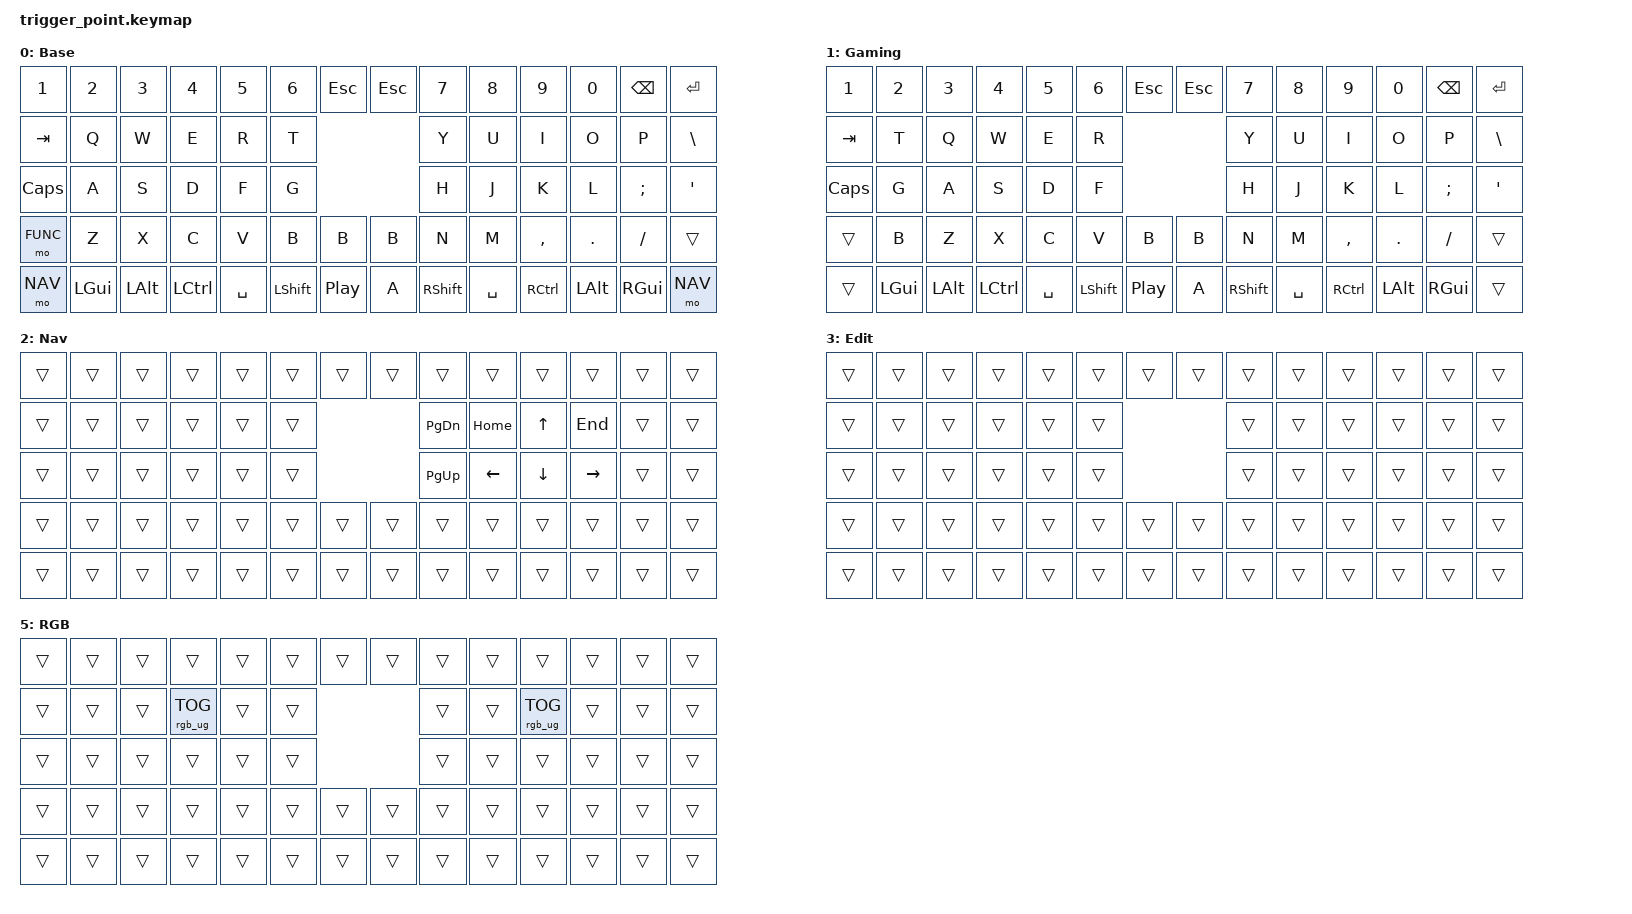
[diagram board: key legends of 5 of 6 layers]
#include <behaviors.dtsi>
#include <dt-bindings/zmk/keys.h>
#include <dt-bindings/zmk/bt.h>
#include <dt-bindings/zmk/outputs.h>
#include <dt-bindings/zmk/rgb.h>

#define BASE    0
#define GAM     1
#define NAV     2
#define EDIT    3
#define FUNC    4
#define RGB     5


#include "combos.dtsi"


/ {
    behaviors {
        rot_kp: sensor_rotate_kp {
            compatible = "zmk,behavior-sensor-rotate-var";
            #sensor-binding-cells = <2>;
            bindings = <&kp>, <&kp>;
        };
    };

    keymap {
        compatible = "zmk,keymap";

        default_layer {
          display-name = "Base";
            sensor-bindings = <&rot_kp C_PREV C_NEXT>, <&rot_kp LEFT RIGHT>;
            // For sensors first is left pot then right pot. CCW then CW
            bindings = <
            // ╭─────────────┬─────────────┬─────────────┬─────────────┬─────────────┬─────────────┬─────────────╮  ╭─────────────┬─────────────┬─────────────┬─────────────┬─────────────┬─────────────┬─────────────╮
            // |   Number 1  |   Number 2  |   Number 3  |   Number 4  |   Number 5  |   Number 6  |    Escape   |  |    Escape   |   Number 7  |   Number 8  |   Number 9  |   Number 0  |  Backspace  |    Enter    |
                    &kp N1        &kp N2        &kp N3        &kp N4        &kp N5        &kp N6       &kp ESC          &kp ESC        &kp N7        &kp N8        &kp N9        &kp N0      &kp BSPC       &kp RET  
            // ├─────────────┼─────────────┼─────────────┼─────────────┼─────────────┼─────────────┼─────────────┤  ├─────────────┼─────────────┼─────────────┼─────────────┼─────────────┼─────────────┼─────────────┤
            // |     Tab     |      Q      |      W      |      E      |      R      |      T      |             |  |             |      Y      |      U      |      I      |       O     |       P     |     Pipe    |
                   &kp TAB        &kp Q         &kp W         &kp E         &kp R         &kp T                                        &kp Y         &kp U         &kp I          &kp O         &kp P      &kp BSLH
            // ├─────────────┼─────────────┼─────────────┼─────────────┼─────────────┼─────────────┼─────────────┤  ├─────────────┼─────────────┼─────────────┼─────────────┼─────────────┼─────────────┼─────────────┤
            // |      ^      |      A      |      S      |      D      |      F      |      G      |             |  |             |      H      |      J      |      K      |      L      |      ;      |  Apostrophe |
                  &kp CAPS        &kp A         &kp S         &kp D         &kp F         &kp G                                        &kp H         &kp J         &kp K          &kp L       &kp SEMI     &kp APOS
            // ├─────────────┼─────────────┼─────────────┼─────────────┼─────────────┼─────────────┼─────────────┤  ├─────────────┼─────────────┼─────────────┼─────────────┼─────────────┼─────────────┼─────────────┤
            // |      ^      |      Z      |      X      |      C      |      V      |      B      |      ^      |  |      ^      |      N      |      M      |      ,      |      .      |      /      |      ^      |
                   &mo FUNC       &kp Z         &kp X         &kp C         &kp V         &kp B         &kp B           &kp B          &kp N         &kp M       &kp COMMA      &kp DOT      &kp SLASH      &trans
            // ├─────────────┼─────────────┼─────────────┼─────────────┼─────────────┼─────────────┼─────────────┤  ├─────────────┼─────────────┼─────────────┼─────────────┼─────────────┼─────────────┼─────────────┤
            // |      ^      |     GUI     |     ALT     |     CTRL    |   space     |    SHIFT    | Play/Pause  |  |      ^      |    SHIFT    |   space     |     CTRL    |     ALT     |     GUI     |      ^      |
                   &mo NAV       &kp LGUI     &kp LALT      &kp LCTRL     &kp SPACE    &kp LSHIFT     &kp C_PP           &kp A       &kp RSHIFT    &kp SPACE     &kp RCTRL     &kp LALT       &kp RGUI     &mo NAV   
            // ╰─────────────┴─────────────┴─────────────┴─────────────┴─────────────┴─────────────┴─────────────╯  ╰─────────────┴─────────────┴─────────────┴─────────────┴─────────────┴─────────────┴─────────────╯
            >;
        };

        gaming_layer {
            display-name = "Gaming";
            sensor-bindings = <&rot_kp C_PREV C_NEXT>, <&rot_kp LEFT RIGHT>;
            bindings = <
            // ╭─────────────┬─────────────┬─────────────┬─────────────┬─────────────┬─────────────┬─────────────╮  ╭─────────────┬─────────────┬─────────────┬─────────────┬─────────────┬─────────────┬─────────────╮
            // |   Number 1  |   Number 2  |   Number 3  |   Number 4  |   Number 5  |   Number 6  |    Escape   |  |    Escape   |   Number 7  |   Number 8  |   Number 9  |   Number 0  |  Backspace  |    Enter    |
                    &kp N1        &kp N2        &kp N3        &kp N4        &kp N5        &kp N6       &kp ESC          &kp ESC        &kp N7        &kp N8        &kp N9        &kp N0      &kp BSPC       &kp RET  
            // ├─────────────┼─────────────┼─────────────┼─────────────┼─────────────┼─────────────┼─────────────┤  ├─────────────┼─────────────┼─────────────┼─────────────┼─────────────┼─────────────┼─────────────┤
            // |     Tab     |      T      |      Q      |      W      |      E      |      R      |             |  |             |      Y      |      U      |      I      |       O     |       P     |     Pipe    |
                   &kp TAB        &kp T         &kp Q         &kp W         &kp E         &kp R                                        &kp Y         &kp U         &kp I          &kp O         &kp P      &kp BSLH
            // ├─────────────┼─────────────┼─────────────┼─────────────┼─────────────┼─────────────┼─────────────┤  ├─────────────┼─────────────┼─────────────┼─────────────┼─────────────┼─────────────┼─────────────┤
            // |      ^      |      G      |      A      |      S      |      D      |      F      |             |  |             |      H      |      J      |      K      |      L      |      ;      |  Apostrophe |
                  &kp CAPS        &kp G         &kp A         &kp S         &kp D         &kp F                                        &kp H         &kp J         &kp K          &kp L       &kp SEMI     &kp APOS
            // ├─────────────┼─────────────┼─────────────┼─────────────┼─────────────┼─────────────┼─────────────┤  ├─────────────┼─────────────┼─────────────┼─────────────┼─────────────┼─────────────┼─────────────┤
            // |      ^      |      B      |      Z      |      X      |      C      |      V      |      ^      |  |      ^      |      N      |      M      |      ,      |      .      |      /      |      ^      |
                   &trans         &kp B         &kp Z         &kp X         &kp C         &kp V         &kp B           &kp B          &kp N         &kp M       &kp COMMA      &kp DOT      &kp SLASH      &trans
            // ├─────────────┼─────────────┼─────────────┼─────────────┼─────────────┼─────────────┼─────────────┤  ├─────────────┼─────────────┼─────────────┼─────────────┼─────────────┼─────────────┼─────────────┤
            // |      ^      |     GUI     |     ALT     |     CTRL    |   space     |    SHIFT    | Play/Pause  |  |      ^      |    SHIFT    |   space     |     CTRL    |     ALT     |     GUI     |      ^      |
                   &trans        &kp LGUI     &kp LALT      &kp LCTRL     &kp SPACE    &kp LSHIFT     &kp C_PP           &kp A       &kp RSHIFT    &kp SPACE     &kp RCTRL     &kp LALT       &kp RGUI      &trans
            // ╰─────────────┴─────────────┴─────────────┴─────────────┴─────────────┴─────────────┴─────────────╯  ╰─────────────┴─────────────┴─────────────┴─────────────┴─────────────┴─────────────┴─────────────╯
            >;
        };

        nav_layer {
            sensor-bindings = <&rot_kp C_PREV C_NEXT>, <&rot_kp LEFT RIGHT>;
            display-name = "Nav";
            bindings = <
            // ╭─────────────┬─────────────┬─────────────┬─────────────┬─────────────┬─────────────┬─────────────╮  ╭─────────────┬─────────────┬─────────────┬─────────────┬─────────────┬─────────────┬─────────────╮
            // |      ^      |      ^      |      ^      |      ^      |      ^      |      ^      |      ^      |  |      ^      |      ^      |      ^      |      ^      |      ^      |      ^      |      ^      |
                   &trans        &trans        &trans        &trans        &trans        &trans        &trans           &trans        &trans        &trans        &trans        &trans        &trans        &trans   
            // ├─────────────┼─────────────┼─────────────┼─────────────┼─────────────┼─────────────┼─────────────┤  ├─────────────┼─────────────┼─────────────┼─────────────┼─────────────┼─────────────┼─────────────┤
            // |      ^      |      ^      |      ^      |      ^      |      ^      |      ^      |             |  |             |   Page Up   |    HOME     |      UP     |     END     |      ^      |      ^      |
                   &trans        &trans        &trans        &trans        &trans        &trans                                      &kp PG_DN      &kp HOME      &kp UP        &kp END       &trans        &trans   
            // ├─────────────┼─────────────┼─────────────┼─────────────┼─────────────┼─────────────┼─────────────┤  ├─────────────┼─────────────┼─────────────┼─────────────┼─────────────┼─────────────┼─────────────┤
            // |      ^      |      ^      |      ^      |      ^      |      ^      |      ^      |             |  |             |  Page Down  |    LEFT     |    DOWN     |   RIGHT     |      ^      |      ^      |
                   &trans        &trans        &trans        &trans        &trans        &trans                                      &kp PG_UP     &kp LEFT      &kp DOWN     &kp RIGHT       &trans        &trans   
            // ├─────────────┼─────────────┼─────────────┼─────────────┼─────────────┼─────────────┼─────────────┤  ├─────────────┼─────────────┼─────────────┼─────────────┼─────────────┼─────────────┼─────────────┤
            // |      ^      |      ^      |      ^      |      ^      |      ^      |      ^      |      ^      |  |      ^      |      ^      |      ^      |      ^      |      ^      |      ^      |      ^      |
                   &trans        &trans        &trans        &trans        &trans        &trans        &trans           &trans        &trans        &trans        &trans        &trans        &trans        &trans   
            // ├─────────────┼─────────────┼─────────────┼─────────────┼─────────────┼─────────────┼─────────────┤  ├─────────────┼─────────────┼─────────────┼─────────────┼─────────────┼─────────────┼─────────────┤
            // |      ^      |      ^      |      ^      |      ^      |      ^      |      ^      |      ^      |  |      ^      |      ^      |      ^      |      ^      |      ^      |      ^      |      ^      |
                   &trans        &trans        &trans        &trans        &trans        &trans        &trans           &trans        &trans        &trans        &trans        &trans        &trans        &trans   
            // ╰─────────────┴─────────────┴─────────────┴─────────────┴─────────────┴─────────────┴─────────────╯  ╰─────────────┴─────────────┴─────────────┴─────────────┴─────────────┴─────────────┴─────────────╯
            >;
        };

        editing_layer {
            sensor-bindings = <&rot_kp C_PREV C_NEXT>, <&rot_kp LEFT RIGHT>;
            display-name = "Edit";
            bindings = <
            // ╭─────────────┬─────────────┬─────────────┬─────────────┬─────────────┬─────────────┬─────────────╮  ╭─────────────┬─────────────┬─────────────┬─────────────┬─────────────┬─────────────┬─────────────╮
            // |      ^      |      ^      |      ^      |      ^      |      ^      |      ^      |      ^      |  |      ^      |      ^      |      ^      |      ^      |      ^      |      ^      |      ^      |
                   &trans        &trans        &trans        &trans        &trans        &trans        &trans           &trans        &trans        &trans        &trans        &trans        &trans        &trans   
            // ├─────────────┼─────────────┼─────────────┼─────────────┼─────────────┼─────────────┼─────────────┤  ├─────────────┼─────────────┼─────────────┼─────────────┼─────────────┼─────────────┼─────────────┤
            // |      ^      |      ^      |      ^      |      ^      |      ^      |      ^      |             |  |             |      ^      |      ^      |      ^      |      ^      |      ^      |      ^      |
                   &trans        &trans        &trans        &trans        &trans        &trans                                       &trans        &trans        &trans        &trans        &trans        &trans   
            // ├─────────────┼─────────────┼─────────────┼─────────────┼─────────────┼─────────────┼─────────────┤  ├─────────────┼─────────────┼─────────────┼─────────────┼─────────────┼─────────────┼─────────────┤
            // |      ^      |      ^      |      ^      |      ^      |      ^      |      ^      |             |  |             |      ^      |      ^      |      ^      |      ^      |      ^      |      ^      |
                   &trans        &trans        &trans        &trans        &trans        &trans                                       &trans        &trans        &trans        &trans        &trans        &trans   
            // ├─────────────┼─────────────┼─────────────┼─────────────┼─────────────┼─────────────┼─────────────┤  ├─────────────┼─────────────┼─────────────┼─────────────┼─────────────┼─────────────┼─────────────┤
            // |      ^      |      ^      |      ^      |      ^      |      ^      |      ^      |      ^      |  |      ^      |      ^      |      ^      |      ^      |      ^      |      ^      |      ^      |
                   &trans        &trans        &trans        &trans        &trans        &trans        &trans           &trans        &trans        &trans        &trans        &trans        &trans        &trans   
            // ├─────────────┼─────────────┼─────────────┼─────────────┼─────────────┼─────────────┼─────────────┤  ├─────────────┼─────────────┼─────────────┼─────────────┼─────────────┼─────────────┼─────────────┤
            // |      ^      |      ^      |      ^      |      ^      |      ^      |      ^      |      ^      |  |      ^      |      ^      |      ^      |      ^      |      ^      |      ^      |      ^      |
                   &trans        &trans        &trans        &trans        &trans        &trans        &trans           &trans        &trans        &trans        &trans        &trans        &trans        &trans   
            // ╰─────────────┴─────────────┴─────────────┴─────────────┴─────────────┴─────────────┴─────────────╯  ╰─────────────┴─────────────┴─────────────┴─────────────┴─────────────┴─────────────┴─────────────╯
            >;
        };

        function_layer {
            sensor-bindings = <&rot_kp C_PREV C_NEXT>, <&rot_kp LEFT RIGHT>;
            display-name = "Func";
            bindings = <
            // ╭─────────────┬─────────────┬─────────────┬─────────────┬─────────────┬─────────────┬─────────────╮  ╭─────────────┬─────────────┬─────────────┬─────────────┬─────────────┬─────────────┬─────────────╮
            // |     F1      |     F2      |     F3      |     F4      |     F5      |     F6      |      ^      |  |      ^      |     F7      |     F8      |     F9      |     F10     |     F11     |     F12     |
                   &kp F1        &kp F2        &kp F3        &kp F4        &kp F5        &kp F6        &trans           &trans        &kp F7        &kp F8        &kp F9        &kp F10       &kp F11      &kp F12    
            // ├─────────────┼─────────────┼─────────────┼─────────────┼─────────────┼─────────────┼─────────────┤  ├─────────────┼─────────────┼─────────────┼─────────────┼─────────────┼─────────────┼─────────────┤
            // |     F13     |     F14     |     F15     |     F16     |     F17     |     F18     |             |  |             |     F19     |     F20     |     F21     |     F22     |     F23     |     F24     |
                   &kp F13       &kp F14       &kp F15       &kp F16        &kp F17      &kp F18                                      &kp F19       &kp F20       &kp F21       &kp F22       &kp F23       &kp F24    
            // ├─────────────┼─────────────┼─────────────┼─────────────┼─────────────┼─────────────┼─────────────┤  ├─────────────┼─────────────┼─────────────┼─────────────┼─────────────┼─────────────┼─────────────┤
            // |      ^      |      ^      |      ^      |      ^      |      ^      |      ^      |             |  |             |      ^      |      ^      |      ^      |      ^      |      ^      |      ^      |
                   &trans        &trans        &trans        &trans        &trans        &trans        &trans           &trans        &trans        &trans        &trans        &trans        &trans        &trans   
            // ├─────────────┼─────────────┼─────────────┼─────────────┼─────────────┼─────────────┼─────────────┤  ├─────────────┼─────────────┼─────────────┼─────────────┼─────────────┼─────────────┼─────────────┤
            // |      ^      |      ^      |      ^      |      ^      |      ^      |      ^      |      ^      |  |      ^      |      ^      |      ^      |      ^      |      ^      |      ^      |      ^      |
                   &trans        &trans        &trans        &trans        &trans        &trans        &trans           &trans        &trans        &trans        &trans        &trans        &trans        &trans   
            // ├─────────────┼─────────────┼─────────────┼─────────────┼─────────────┼─────────────┼─────────────┤  ├─────────────┼─────────────┼─────────────┼─────────────┼─────────────┼─────────────┼─────────────┤
            // |      ^      |      ^      |      ^      |      ^      |      ^      |      ^      |      ^      |  |      ^      |      ^      |      ^      |      ^      |      ^      |      ^      |      ^      |
                &studio_unlock   &trans        &trans        &trans        &trans        &trans        &trans           &trans        &trans        &trans        &trans        &trans        &trans        &trans   
            // ╰─────────────┴─────────────┴─────────────┴─────────────┴─────────────┴─────────────┴─────────────╯  ╰─────────────┴─────────────┴─────────────┴─────────────┴─────────────┴─────────────┴─────────────╯
            >;
        };

        rgb_layer {
            sensor-bindings = <&rot_kp C_PREV C_NEXT>, <&rot_kp LEFT RIGHT>;
            display-name = "RGB";
            bindings = <
            // ╭─────────────┬─────────────┬─────────────┬─────────────┬─────────────┬─────────────┬─────────────╮  ╭─────────────┬─────────────┬─────────────┬─────────────┬─────────────┬─────────────┬─────────────╮
            // |      ^      |      ^      |      ^      |      ^      |      ^      |      ^      |      ^      |  |      ^      |      ^      |      ^      |      ^      |      ^      |      ^      |      ^      |
                   &trans        &trans        &trans        &trans        &trans        &trans        &trans           &trans        &trans        &trans        &trans        &trans        &trans        &trans   
            // ├─────────────┼─────────────┼─────────────┼─────────────┼─────────────┼─────────────┼─────────────┤  ├─────────────┼─────────────┼─────────────┼─────────────┼─────────────┼─────────────┼─────────────┤
            // |      ^      |      ^      |      ^      |      ^      |      ^      |      ^      |             |  |             |      ^      |      ^      |      ^      |      ^      |      ^      |      ^      |
                   &trans        &trans        &trans    &rgb_ug RGB_TOG   &trans        &trans                                       &trans        &trans    &rgb_ug RGB_TOG   &trans        &trans        &trans   
            // ├─────────────┼─────────────┼─────────────┼─────────────┼─────────────┼─────────────┼─────────────┤  ├─────────────┼─────────────┼─────────────┼─────────────┼─────────────┼─────────────┼─────────────┤
            // |      ^      |      ^      |      ^      |      ^      |      ^      |      ^      |             |  |             |      ^      |      ^      |      ^      |      ^      |      ^      |      ^      |
                   &trans        &trans        &trans        &trans        &trans        &trans                                       &trans        &trans        &trans        &trans        &trans        &trans   
            // ├─────────────┼─────────────┼─────────────┼─────────────┼─────────────┼─────────────┼─────────────┤  ├─────────────┼─────────────┼─────────────┼─────────────┼─────────────┼─────────────┼─────────────┤
            // |      ^      |      ^      |      ^      |      ^      |      ^      |      ^      |      ^      |  |      ^      |      ^      |      ^      |      ^      |      ^      |      ^      |      ^      |
                   &trans        &trans        &trans        &trans        &trans        &trans        &trans           &trans        &trans        &trans        &trans        &trans        &trans        &trans   
            // ├─────────────┼─────────────┼─────────────┼─────────────┼─────────────┼─────────────┼─────────────┤  ├─────────────┼─────────────┼─────────────┼─────────────┼─────────────┼─────────────┼─────────────┤
            // |      ^      |      ^      |      ^      |      ^      |      ^      |      ^      |      ^      |  |      ^      |      ^      |      ^      |      ^      |      ^      |      ^      |      ^      |
                   &trans        &trans        &trans        &trans        &trans        &trans        &trans           &trans        &trans        &trans        &trans        &trans        &trans        &trans   
            // ╰─────────────┴─────────────┴─────────────┴─────────────┴─────────────┴─────────────┴─────────────╯  ╰─────────────┴─────────────┴─────────────┴─────────────┴─────────────┴─────────────┴─────────────╯
            >;
        };
    };
};

